# WLR089U0 register map
Vendor: Microchip Technology; Series: WLR089; File version: 0
CPU: CM0+ r0p0, selectable endian, no MPU, no FPU, VTOR, 2 interrupt priority bits
Registers are 32-bit, read-write, reset 0x0 unless marked. A register's access mark holds for its fields unless they carry their own. Offsets are from the block's base; [hi:lo] are bit positions; {n}, {i} and the like mark numbered series; 'fields as' and 'values as' point back to an identical list.

## AES — Advanced Encryption Standard
Base 0x42003400; register names take the prefix AES_
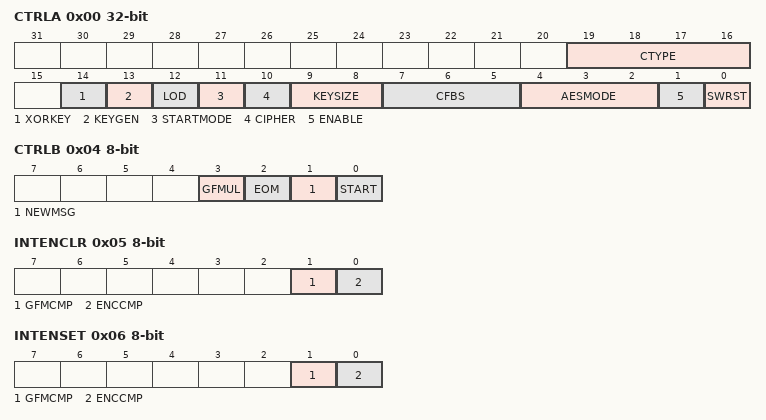
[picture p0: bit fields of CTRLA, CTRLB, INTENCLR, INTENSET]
0x00 CTRLA — Control A
  [19:16] CTYPE — Counter measure types
  [14] XORKEY — Xor Key operation
  [13] KEYGEN — Last key generation
  [12] LOD — LOD Enable
  [11] STARTMODE
  [10] CIPHER — Cipher mode
  [9:8] KEYSIZE
  [7:5] CFBS — CFB Types
  [4:2] AESMODE — AES Modes of operation
  [1] ENABLE
  [0] SWRST — Software Reset
0x04 CTRLB 8-bit — Control B
  [3] GFMUL — GF Multiplication
  [2] EOM — End of message
  [1] NEWMSG — New message
  [0] START — Manual Start
0x05 INTENCLR 8-bit — Interrupt Enable Clear
  [1] GFMCMP — GF Multiplication Complete
  [0] ENCCMP — Encryption Complete
0x06 INTENSET 8-bit — Interrupt Enable Set
  fields as INTENCLR
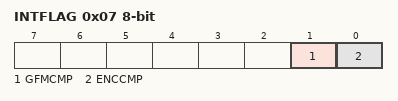
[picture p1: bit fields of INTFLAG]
0x07 INTFLAG 8-bit — Interrupt Flag Status
  fields as INTENCLR
0x08 DATABUFPTR 8-bit — Data buffer pointer
  [1:0] INDATAPTR — Input Data Pointer
0x09 DBGCTRL 8-bit wo — Debug control
  [0] DBGRUN — Debug Run
{0xC+4i} KEYWORD[{i}] (i=0..7) wo — Keyword n
0x38 INDATA
{0x3C+4i} INTVECTV[{i}] (i=0..3) wo — Initialisation Vector n
{0x5C+4i} HASHKEY[{i}] (i=0..3) — Hash key n
{0x6C+4i} GHASH[{i}] (i=0..3) — Galois Hash n
0x80 CIPLEN — Cipher Length
0x84 RANDSEED — Random Seed

## CCL — Configurable Custom Logic
Base 0x43001C00; register names take the prefix CCL_
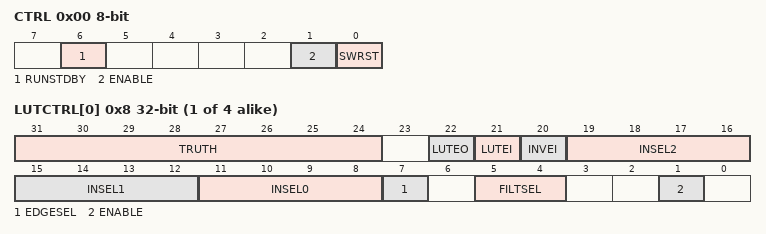
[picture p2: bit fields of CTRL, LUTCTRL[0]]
0x00 CTRL 8-bit — Control
  [6] RUNSTDBY — Run in Standby
    0=DISABLE (Generic clock is not required in standby sleep mode); 1=ENABLE (Generic clock is required in standby sleep mode)
  [1] ENABLE
    0=DISABLE (The peripheral is disabled); 1=ENABLE (The peripheral is enabled)
  [0] SWRST — Software Reset
    0=DISABLE (The peripheral is not reset); 1=ENABLE (The peripheral is reset)
{0x4+i} SEQCTRL[{i}] (i=0..1) 8-bit — SEQ Control x
  [3:0] SEQSEL — Sequential Selection
    0=DISABLE (Sequential logic is disabled); 1=DFF (D flip flop); 2=JK (JK flip flop); 3=LATCH (D latch); 4=RS (RS latch)
{0x8+4i} LUTCTRL[{i}] (i=0..3) — LUT Control x
  [31:24] TRUTH — Truth Value
  [22] LUTEO — LUT Event Output Enable
    0=DISABLE (LUT event output is disabled); 1=ENABLE (LUT event output is enabled)
  [21] LUTEI — LUT Event Input Enable
    0=DISABLE (LUT incoming event is disabled); 1=ENABLE (LUT incoming event is enabled)
  [20] INVEI — Inverted Event Input Enable
    0=DISABLE (Incoming event is not inverted); 1=ENABLE (Incoming event is inverted)
  [19:16] INSEL2 — Input Selection 2
    0=MASK (Masked input); 1=FEEDBACK (Feedback input source); 2=LINK (Linked LUT input source); 3=EVENT (Event input source); 4=IO (I/O pin input source); 5=AC (AC input source); 6=TC (TC input source); 7=ALTTC (Alternate TC input source); 8=TCC (TCC input source); 9=SERCOM (SERCOM input source)
  [15:12] INSEL1 — Input Selection 1
    values as INSEL2
  [11:8] INSEL0 — Input Selection 0
    values as INSEL2
  [7] EDGESEL — Edge Selection
    0=DISABLE (Edge detector is disabled); 1=ENABLE (Edge detector is enabled)
  [5:4] FILTSEL — Filter Selection
    0=DISABLE (Filter disabled); 1=SYNCH (Synchronizer enabled); 2=FILTER (Filter enabled)
  [1] ENABLE — LUT Enable
    0=DISABLE (LUT block is disabled); 1=ENABLE (LUT block is enabled)

## DSU — Device Service Unit
Base 0x41002000; register names take the prefix DSU_
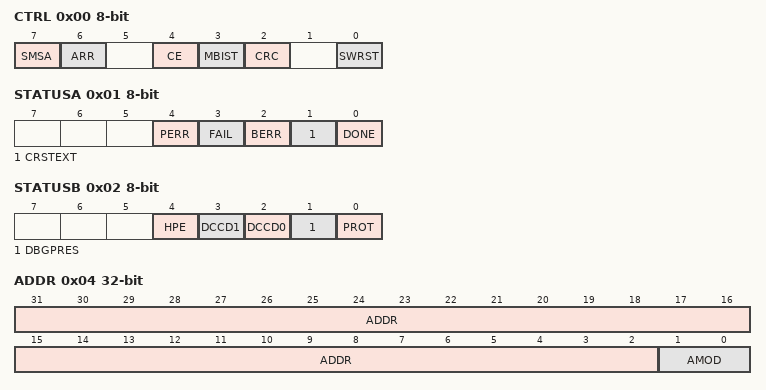
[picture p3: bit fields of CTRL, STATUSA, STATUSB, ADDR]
0x00 CTRL 8-bit wo — Control
  [7] SMSA — Start Memory Stream Access
  [6] ARR — Auxiliary Row Read
  [4] CE — Chip-Erase
  [3] MBIST — Memory built-in self-test
  [2] CRC — 32-bit Cyclic Redundancy Code
  [0] SWRST — Software Reset
0x01 STATUSA 8-bit
  [4] PERR — Protection Error
  [3] FAIL — Failure
  [2] BERR — Bus Error
  [1] CRSTEXT — CPU Reset Phase Extension
  [0] DONE
0x02 STATUSB 8-bit ro
  [4] HPE — Hot-Plugging Enable
  [3] DCCD1 — Debug Communication Channel 1 Dirty
  [2] DCCD0 — Debug Communication Channel 0 Dirty
  [1] DBGPRES — Debugger Present
  [0] PROT — Protected
0x04 ADDR — Address
  [31:2] ADDR — Address
  [1:0] AMOD — Access Mode
0x08 LENGTH
  [31:2] LENGTH
0x0C DATA
{0x10+4i} DCC[{i}] (i=0..1) — Debug Communication Channel n
  [31:0] DATA
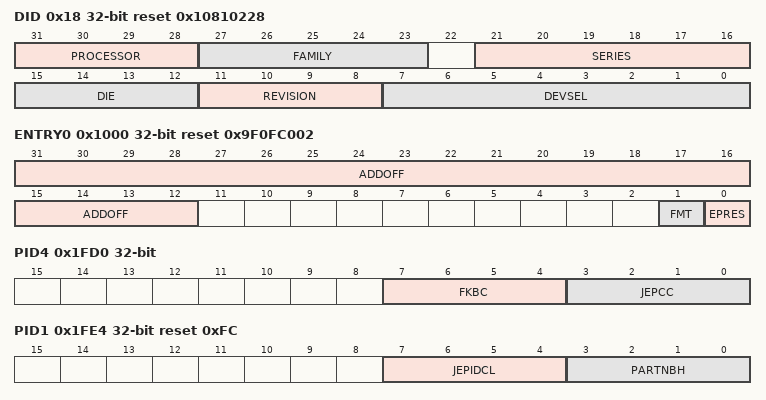
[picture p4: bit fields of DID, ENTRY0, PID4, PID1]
0x18 DID ro reset 0x10810228 — Device Identification
  [31:28] PROCESSOR
    0=Cortex-M0; 1=Cortex-M0+; 2=Cortex-M3; 3=Cortex-M4
  [27:23] FAMILY
    0=General purpose microcontroller; 1=PicoPower
  [21:16] SERIES
    0=Cortex-M0+ processor, basic feature set; 1=Cortex-M0+ processor, USB
  [15:12] DIE — Die Number
  [11:8] REVISION — Revision Number
  [7:0] DEVSEL — Device Select
{0xF0+4i} DCFG[{i}] (i=0..1) — Device Configuration
  [31:0] DCFG
0x1000 ENTRY0 ro reset 0x9F0FC002 — Coresight ROM Table Entry 0
  [31:12] ADDOFF — Address Offset
  [1] FMT — Format
  [0] EPRES — Entry Present
0x1004 ENTRY1 ro reset 0x3002 — Coresight ROM Table Entry 1
0x1008 END ro — Coresight ROM Table End
  [31:0] END — End Marker
0x1FCC MEMTYPE ro — Coresight ROM Table Memory Type
  [0] SMEMP — System Memory Present
0x1FD0 PID4 ro — Peripheral Identification 4
  [7:4] FKBC — 4KB count
  [3:0] JEPCC — JEP-106 Continuation Code
{0x1FC0+4i} PID{i} ro (i=5..7) — Peripheral Identification {i}
0x1FE0 PID0 ro reset 0xD0 — Peripheral Identification 0
  [7:0] PARTNBL — Part Number Low
0x1FE4 PID1 ro reset 0xFC — Peripheral Identification 1
  [7:4] JEPIDCL — Low part of the JEP-106 Identity Code
  [3:0] PARTNBH — Part Number High
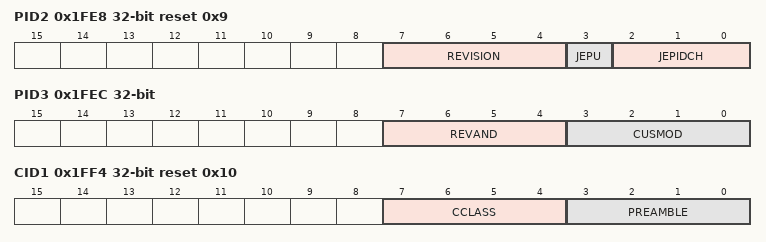
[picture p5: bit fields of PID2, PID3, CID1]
0x1FE8 PID2 ro reset 0x9 — Peripheral Identification 2
  [7:4] REVISION — Revision Number
  [3] JEPU — JEP-106 Identity Code is used
  [2:0] JEPIDCH — JEP-106 Identity Code High
0x1FEC PID3 ro — Peripheral Identification 3
  [7:4] REVAND — Revision Number
  [3:0] CUSMOD — ARM CUSMOD
0x1FF0 CID0 ro reset 0xD — Component Identification 0
  [7:0] PREAMBLEB0 — Preamble Byte 0
0x1FF4 CID1 ro reset 0x10 — Component Identification 1
  [7:4] CCLASS — Component Class
  [3:0] PREAMBLE
0x1FF8 CID2 ro reset 0x5 — Component Identification 2
  [7:0] PREAMBLEB2 — Preamble Byte 2
0x1FFC CID3 ro reset 0xB1 — Component Identification 3
  [7:0] PREAMBLEB3 — Preamble Byte 3

## Notices in the file
Copyright (c) 2017 Microchip Technology Inc.
SPDX-License-Identifier: Apache-2.0
Licensed under the Apache License, Version 2.0 (the "License");
you may not use this file except in compliance with the License.
You may obtain a copy of the License at
http://www.apache.org/licenses/LICENSE-2.0
Unless required by applicable law or agreed to in writing, software
distributed under the License is distributed on an "AS IS" BASIS,
WITHOUT WARRANTIES OR CONDITIONS OF ANY KIND, either express or implied.
See the License for the specific language governing permissions and
limitations under the License.
